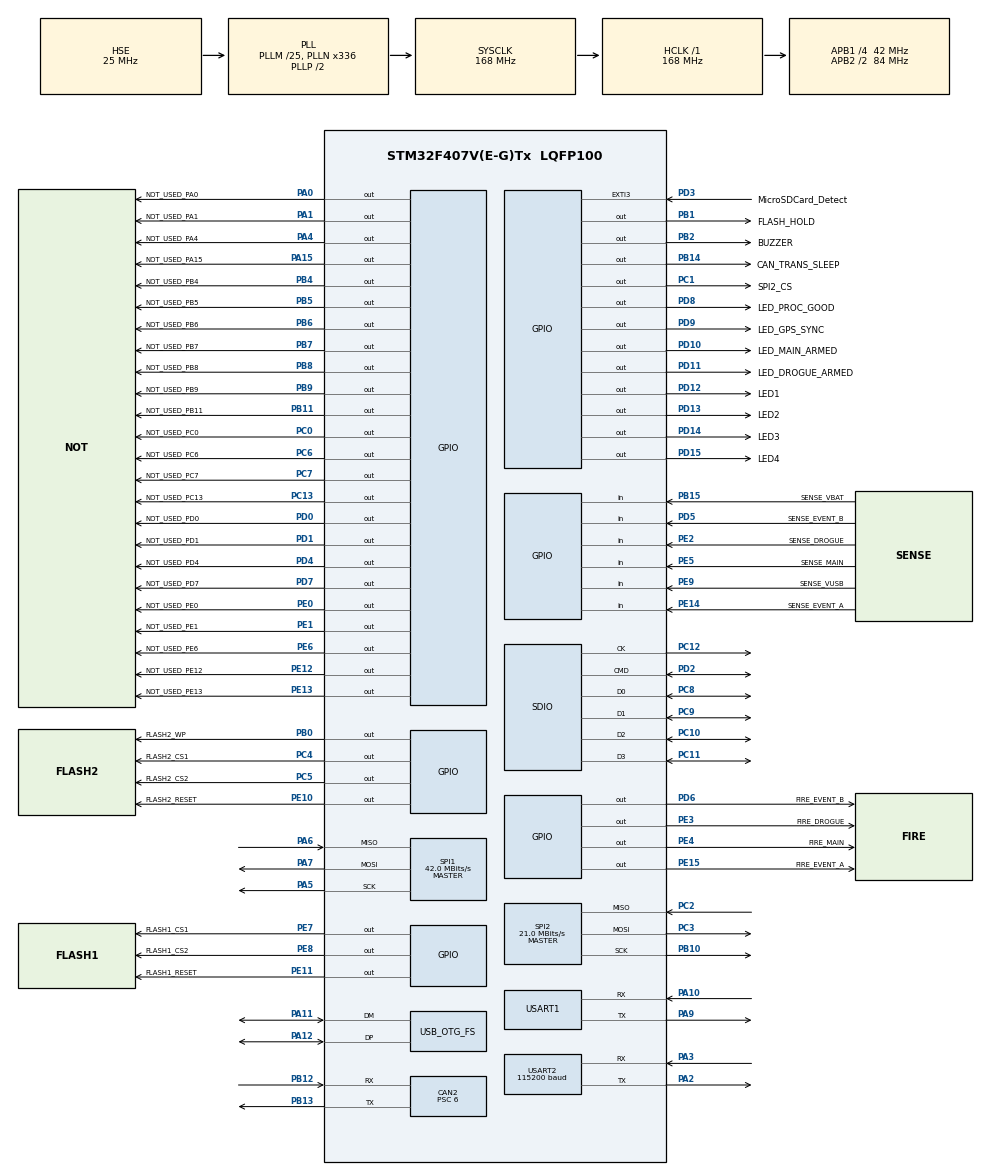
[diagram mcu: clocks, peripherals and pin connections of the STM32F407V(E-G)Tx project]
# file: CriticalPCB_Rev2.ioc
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CAN2.BS1=CAN_BS1_11TQ
CAN2.BS2=CAN_BS2_2TQ
CAN2.CalculateTimeBit=2000
CAN2.CalculateTimeQuantum=142.85714285714286
CAN2.Prescaler=6
Dma.Request0=USART2_TX
Dma.Request1=SDIO
Dma.SDIO.1.Direction=DMA_PERIPH_TO_MEMORY
Dma.SDIO.1.FIFOMode=DMA_FIFOMODE_ENABLE
Dma.SDIO.1.FIFOThreshold=DMA_FIFO_THRESHOLD_FULL
Dma.SDIO.1.Instance=DMA2_Stream3
Dma.SDIO.1.MemBurst=DMA_MBURST_INC4
Dma.SDIO.1.MemDataAlignment=DMA_MDATAALIGN_WORD
Dma.SDIO.1.MemInc=DMA_MINC_ENABLE
Dma.SDIO.1.Mode=DMA_PFCTRL
Dma.SDIO.1.PeriphBurst=DMA_PBURST_INC4
Dma.SDIO.1.PeriphDataAlignment=DMA_PDATAALIGN_WORD
Dma.SDIO.1.PeriphInc=DMA_PINC_DISABLE
Dma.SDIO.1.Priority=DMA_PRIORITY_VERY_HIGH
Dma.USART2_TX.0.Direction=DMA_MEMORY_TO_PERIPH
Dma.USART2_TX.0.FIFOMode=DMA_FIFOMODE_DISABLE
Dma.USART2_TX.0.Instance=DMA1_Stream6
Dma.USART2_TX.0.MemDataAlignment=DMA_MDATAALIGN_BYTE
Dma.USART2_TX.0.MemInc=DMA_MINC_ENABLE
Dma.USART2_TX.0.Mode=DMA_NORMAL
Dma.USART2_TX.0.PeriphDataAlignment=DMA_PDATAALIGN_BYTE
Dma.USART2_TX.0.PeriphInc=DMA_PINC_DISABLE
Dma.USART2_TX.0.Priority=DMA_PRIORITY_VERY_HIGH
FATFS._FS_LOCK=10
Mcu.Family=STM32F4
Mcu.Name=STM32F407V(E-G)Tx
Mcu.Package=LQFP100
NVIC.CAN2_RX0_IRQn=true\:1\:0\:true\:true\:true\:10\:true
NVIC.CAN2_RX1_IRQn=true\:1\:0\:true\:true\:true\:11\:true
NVIC.DMA1_Stream6_IRQn=true\:0\:0\:false\:true\:true\:7\:true
NVIC.DMA2_Stream3_IRQn=true\:0\:0\:false\:true\:true\:9\:true
NVIC.EXTI3_IRQn=true\:1\:0\:true\:true\:true\:4\:true
NVIC.OTG_FS_IRQn=true\:1\:0\:true\:true\:true\:12\:true
NVIC.PriorityGroup=NVIC_PRIORITYGROUP_4
NVIC.SDIO_IRQn=true\:0\:0\:false\:true\:true\:8\:true
NVIC.TIM1_UP_TIM10_IRQn=true\:4\:0\:true\:true\:true\:1\:true
NVIC.TIM2_IRQn=true\:0\:0\:false\:true\:true\:2\:true
NVIC.USART1_IRQn=true\:1\:0\:true\:true\:true\:5\:true
NVIC.USART2_IRQn=true\:1\:0\:true\:true\:true\:6\:true
PA0-WKUP.GPIO_Label=NOT_USED_PA0
PA0-WKUP.GPIO_PuPd=GPIO_PULLDOWN
PA0-WKUP.Signal=GPIO_Output
PA1.GPIO_Label=NOT_USED_PA1
PA1.GPIO_PuPd=GPIO_PULLDOWN
PA1.Signal=GPIO_Output
PA10.GPIO_PuPd=GPIO_PULLUP
PA10.Mode=Asynchronous
PA10.Signal=USART1_RX
PA11.Mode=Device_Only
PA11.Signal=USB_OTG_FS_DM
PA12.Mode=Device_Only
PA12.Signal=USB_OTG_FS_DP
PA13.Mode=Serial_Wire
PA13.Signal=SYS_JTMS-SWDIO
PA14.Mode=Serial_Wire
PA14.Signal=SYS_JTCK-SWCLK
PA15.GPIO_Label=NOT_USED_PA15
PA15.GPIO_PuPd=GPIO_PULLDOWN
PA15.Signal=GPIO_Output
PA2.Mode=Asynchronous
PA2.Signal=USART2_TX
PA3.Mode=Asynchronous
PA3.Signal=USART2_RX
PA4.GPIO_Label=NOT_USED_PA4
PA4.GPIO_PuPd=GPIO_PULLDOWN
PA4.Signal=GPIO_Output
PA5.Mode=Full_Duplex_Master
PA5.Signal=SPI1_SCK
PA6.Mode=Full_Duplex_Master
PA6.Signal=SPI1_MISO
PA7.Mode=Full_Duplex_Master
PA7.Signal=SPI1_MOSI
PA9.GPIO_PuPd=GPIO_PULLUP
PA9.Mode=Asynchronous
PA9.Signal=USART1_TX
PB0.GPIO_Label=FLASH2_WP
PB0.GPIO_PuPd=GPIO_PULLUP
PB0.GPIO_Speed=GPIO_SPEED_FREQ_VERY_HIGH
PB0.PinState=GPIO_PIN_SET
PB0.Signal=GPIO_Output
PB1.GPIO_Label=FLASH_HOLD
PB1.GPIO_PuPd=GPIO_PULLUP
PB1.GPIO_Speed=GPIO_SPEED_FREQ_VERY_HIGH
PB1.PinState=GPIO_PIN_SET
PB1.Signal=GPIO_Output
PB10.Mode=Full_Duplex_Master
PB10.Signal=SPI2_SCK
PB11.GPIO_Label=NOT_USED_PB11
PB11.GPIO_PuPd=GPIO_PULLDOWN
PB11.Signal=GPIO_Output
PB12.GPIO_PuPd=GPIO_PULLUP
PB12.Mode=Slave
PB12.Signal=CAN2_RX
PB13.GPIO_PuPd=GPIO_PULLUP
PB13.Mode=Slave
PB13.Signal=CAN2_TX
PB14.GPIO_Label=CAN_TRANS_SLEEP
PB14.GPIO_PuPd=GPIO_PULLDOWN
PB14.GPIO_Speed=GPIO_SPEED_FREQ_VERY_HIGH
PB14.Signal=GPIO_Output
PB15.GPIO_Label=SENSE_VBAT
PB15.Signal=GPIO_Input
PB2.GPIO_Label=BUZZER
PB2.GPIO_PuPd=GPIO_PULLDOWN
PB2.Signal=GPIO_Output
PB3.Signal=SYS_JTDO-SWO
PB4.GPIO_Label=NOT_USED_PB4
PB4.GPIO_PuPd=GPIO_PULLDOWN
PB4.Signal=GPIO_Output
PB5.GPIO_Label=NOT_USED_PB5
PB5.GPIO_PuPd=GPIO_PULLDOWN
PB5.Signal=GPIO_Output
PB6.GPIO_Label=NOT_USED_PB6
PB6.GPIO_PuPd=GPIO_PULLDOWN
PB6.Signal=GPIO_Output
PB7.GPIO_Label=NOT_USED_PB7
PB7.GPIO_PuPd=GPIO_PULLDOWN
PB7.Signal=GPIO_Output
PB8.GPIO_Label=NOT_USED_PB8
PB8.GPIO_PuPd=GPIO_PULLDOWN
PB8.Signal=GPIO_Output
PB9.GPIO_Label=NOT_USED_PB9
PB9.GPIO_PuPd=GPIO_PULLDOWN
PB9.Signal=GPIO_Output
PC0.GPIO_Label=NOT_USED_PC0
PC0.GPIO_PuPd=GPIO_PULLDOWN
PC0.Signal=GPIO_Output
PC1.GPIO_Label=SPI2_CS
PC1.GPIO_PuPd=GPIO_PULLUP
PC1.GPIO_Speed=GPIO_SPEED_FREQ_VERY_HIGH
PC1.PinState=GPIO_PIN_SET
PC1.Signal=GPIO_Output
PC10.GPIO_PuPd=GPIO_PULLUP
PC10.Mode=SD_4_bits_Wide_bus
PC10.Signal=SDIO_D2
PC11.GPIO_PuPd=GPIO_PULLUP
PC11.Mode=SD_4_bits_Wide_bus
PC11.Signal=SDIO_D3
PC12.GPIO_PuPd=GPIO_PULLUP
PC12.Mode=SD_4_bits_Wide_bus
PC12.Signal=SDIO_CK
PC13-ANTI_TAMP.GPIO_Label=NOT_USED_PC13
PC13-ANTI_TAMP.GPIO_PuPd=GPIO_PULLDOWN
PC13-ANTI_TAMP.Signal=GPIO_Output
PC14-OSC32_IN.Mode=LSE-External-Oscillator
PC14-OSC32_IN.Signal=RCC_OSC32_IN
PC15-OSC32_OUT.Mode=LSE-External-Oscillator
PC15-OSC32_OUT.Signal=RCC_OSC32_OUT
PC2.Mode=Full_Duplex_Master
PC2.Signal=SPI2_MISO
PC3.Mode=Full_Duplex_Master
PC3.Signal=SPI2_MOSI
PC4.GPIO_Label=FLASH2_CS1
PC4.GPIO_PuPd=GPIO_PULLUP
PC4.GPIO_Speed=GPIO_SPEED_FREQ_VERY_HIGH
PC4.PinState=GPIO_PIN_SET
PC4.Signal=GPIO_Output
PC5.GPIO_Label=FLASH2_CS2
PC5.GPIO_PuPd=GPIO_PULLUP
PC5.GPIO_Speed=GPIO_SPEED_FREQ_VERY_HIGH
PC5.PinState=GPIO_PIN_SET
PC5.Signal=GPIO_Output
PC6.GPIO_Label=NOT_USED_PC6
PC6.GPIO_PuPd=GPIO_PULLDOWN
PC6.Signal=GPIO_Output
PC7.GPIO_Label=NOT_USED_PC7
PC7.GPIO_PuPd=GPIO_PULLDOWN
PC7.Signal=GPIO_Output
PC8.GPIO_PuPd=GPIO_PULLUP
PC8.Mode=SD_4_bits_Wide_bus
PC8.Signal=SDIO_D0
PC9.GPIO_PuPd=GPIO_PULLUP
PC9.Mode=SD_4_bits_Wide_bus
PC9.Signal=SDIO_D1
PD0.GPIO_Label=NOT_USED_PD0
PD0.GPIO_PuPd=GPIO_PULLDOWN
PD0.Signal=GPIO_Output
PD1.GPIO_Label=NOT_USED_PD1
PD1.GPIO_PuPd=GPIO_PULLDOWN
PD1.Signal=GPIO_Output
PD10.GPIO_Label=LED_MAIN_ARMED
PD10.GPIO_PuPd=GPIO_PULLDOWN
PD10.Signal=GPIO_Output
PD11.GPIO_Label=LED_DROGUE_ARMED
PD11.GPIO_PuPd=GPIO_PULLDOWN
PD11.Signal=GPIO_Output
PD12.GPIO_Label=LED1
PD12.GPIO_PuPd=GPIO_PULLDOWN
PD12.Signal=GPIO_Output
PD13.GPIO_Label=LED2
PD13.GPIO_PuPd=GPIO_PULLDOWN
PD13.Signal=GPIO_Output
PD14.GPIO_Label=LED3
PD14.GPIO_PuPd=GPIO_PULLDOWN
PD14.Signal=GPIO_Output
PD15.GPIO_Label=LED4
PD15.GPIO_PuPd=GPIO_PULLDOWN
PD15.Signal=GPIO_Output
PD2.GPIO_PuPd=GPIO_PULLUP
PD2.Mode=SD_4_bits_Wide_bus
PD2.Signal=SDIO_CMD
PD3.GPIO_Label=MicroSDCard_Detect
PD3.GPIO_ModeDefaultEXTI=GPIO_MODE_IT_RISING_FALLING
PD3.GPIO_PuPd=GPIO_PULLDOWN
PD3.Signal=GPXTI3
PD4.GPIO_Label=NOT_USED_PD4
PD4.GPIO_PuPd=GPIO_PULLDOWN
PD4.Signal=GPIO_Output
PD5.GPIO_Label=SENSE_EVENT_B
PD5.GPIO_PuPd=GPIO_PULLUP
PD5.Signal=GPIO_Input
PD6.GPIO_Label=FIRE_EVENT_B
PD6.GPIO_PuPd=GPIO_PULLDOWN
PD6.GPIO_Speed=GPIO_SPEED_FREQ_VERY_HIGH
PD6.Signal=GPIO_Output
PD7.GPIO_Label=NOT_USED_PD7
PD7.GPIO_PuPd=GPIO_PULLDOWN
PD7.Signal=GPIO_Output
PD8.GPIO_Label=LED_PROC_GOOD
PD8.GPIO_PuPd=GPIO_PULLDOWN
PD8.Signal=GPIO_Output
PD9.GPIO_Label=LED_GPS_SYNC
PD9.GPIO_PuPd=GPIO_PULLDOWN
PD9.Signal=GPIO_Output
PE0.GPIO_Label=NOT_USED_PE0
PE0.GPIO_PuPd=GPIO_PULLDOWN
PE0.Signal=GPIO_Output
PE1.GPIO_Label=NOT_USED_PE1
PE1.GPIO_PuPd=GPIO_PULLDOWN
PE1.Signal=GPIO_Output
PE10.GPIO_Label=FLASH2_RESET
PE10.GPIO_PuPd=GPIO_PULLUP
PE10.GPIO_Speed=GPIO_SPEED_FREQ_VERY_HIGH
PE10.PinState=GPIO_PIN_SET
PE10.Signal=GPIO_Output
PE11.GPIO_Label=FLASH1_RESET
PE11.GPIO_PuPd=GPIO_PULLUP
PE11.GPIO_Speed=GPIO_SPEED_FREQ_VERY_HIGH
PE11.PinState=GPIO_PIN_SET
PE11.Signal=GPIO_Output
PE12.GPIO_Label=NOT_USED_PE12
PE12.GPIO_PuPd=GPIO_PULLDOWN
PE12.Signal=GPIO_Output
PE13.GPIO_Label=NOT_USED_PE13
PE13.GPIO_PuPd=GPIO_PULLDOWN
PE13.Signal=GPIO_Output
PE14.GPIO_Label=SENSE_EVENT_A
PE14.GPIO_PuPd=GPIO_PULLUP
PE14.Signal=GPIO_Input
PE15.GPIO_Label=FIRE_EVENT_A
PE15.GPIO_PuPd=GPIO_PULLDOWN
PE15.GPIO_Speed=GPIO_SPEED_FREQ_VERY_HIGH
PE15.Signal=GPIO_Output
PE2.GPIO_Label=SENSE_DROGUE
PE2.GPIO_PuPd=GPIO_PULLUP
PE2.Signal=GPIO_Input
PE3.GPIO_Label=FIRE_DROGUE
PE3.GPIO_PuPd=GPIO_PULLDOWN
PE3.GPIO_Speed=GPIO_SPEED_FREQ_VERY_HIGH
PE3.Signal=GPIO_Output
PE4.GPIO_Label=FIRE_MAIN
PE4.GPIO_PuPd=GPIO_PULLDOWN
PE4.GPIO_Speed=GPIO_SPEED_FREQ_VERY_HIGH
PE4.Signal=GPIO_Output
PE5.GPIO_Label=SENSE_MAIN
PE5.GPIO_PuPd=GPIO_PULLUP
PE5.Signal=GPIO_Input
PE6.GPIO_Label=NOT_USED_PE6
PE6.GPIO_PuPd=GPIO_PULLDOWN
PE6.Signal=GPIO_Output
PE7.GPIO_Label=FLASH1_CS1
PE7.GPIO_PuPd=GPIO_PULLUP
PE7.GPIO_Speed=GPIO_SPEED_FREQ_VERY_HIGH
PE7.PinState=GPIO_PIN_SET
PE7.Signal=GPIO_Output
PE8.GPIO_Label=FLASH1_CS2
PE8.GPIO_PuPd=GPIO_PULLUP
PE8.GPIO_Speed=GPIO_SPEED_FREQ_VERY_HIGH
PE8.PinState=GPIO_PIN_SET
PE8.Signal=GPIO_Output
PE9.GPIO_Label=SENSE_VUSB
PE9.GPIO_PuPd=GPIO_PULLUP
PE9.Signal=GPIO_Input
PH0-OSC_IN.Mode=HSE-External-Clock-Source
PH0-OSC_IN.Signal=RCC_OSC_IN
PH1-OSC_OUT.Mode=HSE-External-Clock-Source
PH1-OSC_OUT.Signal=RCC_OSC_OUT
ProjectManager.HeapSize=0x200
ProjectManager.StackSize=0x400
ProjectManager.TargetToolchain=Makefile
RCC.48MHZClocksFreq_Value=48000000
RCC.AHBCLKDivider=RCC_SYSCLK_DIV1
RCC.AHBFreq_Value=168000000
RCC.APB1CLKDivider=RCC_HCLK_DIV4
RCC.APB1Freq_Value=42000000
RCC.APB1TimFreq_Value=84000000
RCC.APB2CLKDivider=RCC_HCLK_DIV2
RCC.APB2Freq_Value=84000000
RCC.APB2TimFreq_Value=168000000
RCC.CortexFreq_Value=168000000
RCC.Cortex_Div=SYSTICK_CLKSOURCE_HCLK
RCC.HCLKFreq_Value=168000000
RCC.HSE_VALUE=25000000
RCC.HSI_VALUE=16000000
RCC.OscillatorTypeHSI=RCC_OSCILLATORTYPE_HSI
RCC.PLLM=25
RCC.PLLN=336
RCC.PLLP=RCC_PLLP_DIV2
RCC.PLLQ=7
RCC.RCC_MCODiv1=RCC_MCODIV_1
RCC.RCC_MCODiv2=RCC_MCODIV_1
RCC.RCC_RTC_Clock_Source=RCC_RTCCLKSOURCE_LSE
RCC.RCC_RTC_Clock_SourceVirtual=RCC_RTCCLKSOURCE_LSE
RCC.RCC_RTC_Clock_Source_FROM_HSE=RCC_RTCCLKSOURCE_HSE_DIV2
RCC.SYSCLKFreq_VALUE=168000000
RCC.SYSCLKSource=RCC_SYSCLKSOURCE_PLLCLK
RCC.VCOOutputFreq_Value=336000000
RTC.Alarm=RTC_ALARM_A
SPI1.CalculateBaudRate=42.0 MBits/s
SPI1.Direction=SPI_DIRECTION_2LINES
SPI1.Mode=SPI_MODE_MASTER
SPI1.VirtualType=VM_MASTER
SPI2.CalculateBaudRate=21.0 MBits/s
SPI2.Direction=SPI_DIRECTION_2LINES
SPI2.Mode=SPI_MODE_MASTER
SPI2.VirtualType=VM_MASTER
TIM1.Period=0x7FFF
TIM1.Prescaler=256
TIM1.TIM_MasterOutputTrigger=TIM_TRGO_UPDATE
TIM1.TIM_MasterSlaveMode=TIM_MASTERSLAVEMODE_ENABLE
TIM2.Period=100
TIM3.Period=20
USART1.VirtualMode=VM_ASYNC
USART2.BaudRate=115200
USART2.VirtualMode=VM_ASYNC
USB_DEVICE.CLASS_NAME_FS=CDC
USB_DEVICE.MANUFACTURER_STRING-CDC_FS=RockETS Master Race
USB_DEVICE.VirtualModeFS=Cdc_FS
USB_OTG_FS.VirtualMode=Device_Only
USB_OTG_FS.dev_endpoints=4
VP_CRC_VS_CRC.Mode=CRC_Activate
VP_FATFS_VS_SDIO.Mode=SDIO
VP_RTC_VS_RTC_Activate.Mode=RTC_Enabled
VP_RTC_VS_RTC_Alarm_A_Intern.Mode=Alarm A
VP_RTC_VS_RTC_Calendar.Mode=RTC_Calendar
VP_TIM1_VS_ClockSourceINT.Mode=Internal
VP_TIM1_VS_ClockSourceITR.Mode=TriggerSource_ITR0
VP_TIM2_VS_ClockSourceITR.Mode=TriggerSource_ITR0
VP_TIM2_VS_ControllerModeClock.Mode=Clock Mode
VP_TIM3_VS_ClockSourceITR.Mode=TriggerSource_ITR0
VP_TIM3_VS_ControllerModeClock.Mode=Clock Mode
VP_USB_DEVICE_VS_USB_DEVICE_CDC_FS.Mode=CDC_FS
board=CriticalPCB_Rev2

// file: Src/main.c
/**
  ******************************************************************************
  * File Name          : main.c
  * Description        : Main program body
  ******************************************************************************
  * This notice applies to any and all portions of this file
  * that are not between comment pairs USER CODE BEGIN and
  * USER CODE END. Other portions of this file, whether
  * inserted by the user or by software development tools
  * are owned by their respective copyright owners.
  *
  * Copyright (c) 2019 STMicroelectronics International N.V.
  * All rights reserved.
  *
  * Redistribution and use in source and binary forms, with or without
  * modification, are permitted, provided that the following conditions are met:
  *
  * 1. Redistribution of source code must retain the above copyright notice,
  *    this list of conditions and the following disclaimer.
  * 2. Redistributions in binary form must reproduce the above copyright notice,
  *    this list of conditions and the following disclaimer in the documentation
  *    and/or other materials provided with the distribution.
  * 3. Neither the name of STMicroelectronics nor the names of other
  *    contributors to this software may be used to endorse or promote products
  *    derived from this software without specific written permission.
  * 4. This software, including modifications and/or derivative works of this
  *    software, must execute solely and exclusively on microcontroller or
  *    microprocessor devices manufactured by or for STMicroelectronics.
  * 5. Redistribution and use of this software other than as permitted under
  *    this license is void and will automatically terminate your rights under
  *    this license.
  *
  * THIS SOFTWARE IS PROVIDED BY STMICROELECTRONICS AND CONTRIBUTORS "AS IS"
  * AND ANY EXPRESS, IMPLIED OR STATUTORY WARRANTIES, INCLUDING, BUT NOT
  * LIMITED TO, THE IMPLIED WARRANTIES OF MERCHANTABILITY, FITNESS FOR A
  * PARTICULAR PURPOSE AND NON-INFRINGEMENT OF THIRD PARTY INTELLECTUAL PROPERTY
  * RIGHTS ARE DISCLAIMED TO THE FULLEST EXTENT PERMITTED BY LAW. IN NO EVENT
  * SHALL STMICROELECTRONICS OR CONTRIBUTORS BE LIABLE FOR ANY DIRECT, INDIRECT,
  * INCIDENTAL, SPECIAL, EXEMPLARY, OR CONSEQUENTIAL DAMAGES (INCLUDING, BUT NOT
  * LIMITED TO, PROCUREMENT OF SUBSTITUTE GOODS OR SERVICES; LOSS OF USE, DATA,
  * OR PROFITS; OR BUSINESS INTERRUPTION) HOWEVER CAUSED AND ON ANY THEORY OF
  * LIABILITY, WHETHER IN CONTRACT, STRICT LIABILITY, OR TORT (INCLUDING
  * NEGLIGENCE OR OTHERWISE) ARISING IN ANY WAY OUT OF THE USE OF THIS SOFTWARE,
  * EVEN IF ADVISED OF THE POSSIBILITY OF SUCH DAMAGE.
  *
  ******************************************************************************
  */
#include "main.h"
#include "stm32f4xx_hal.h"
#include "can.h"
#include "crc.h"
#include "dma.h"
#include "fatfs.h"
#include "rtc.h"
#include "sdio.h"
#include "spi.h"
#include "tim.h"
#include "usart.h"
#include "usb_device.h"
#include "gpio.h"

/* USER CODE BEGIN PV */
/* Private variables ---------------------------------------------------------*/

/* USER CODE END PV */

void SystemClock_Config(void);
static void MX_NVIC_Init(void);

/* USER CODE BEGIN PFP */
/* Private function prototypes -----------------------------------------------*/

/* USER CODE END PFP */

int main(void)
{

  /* MCU Configuration----------------------------------------------------------*/

  /* Reset of all peripherals, Initializes the Flash interface and the Systick. */
  HAL_Init();

  /* Configure the system clock */
  SystemClock_Config();

  /* Initialize all configured peripherals */
  MX_GPIO_Init();
  MX_DMA_Init();
  MX_CAN2_Init();
  MX_RTC_Init();
  MX_SDIO_SD_Init();
  MX_SPI1_Init();
  MX_SPI2_Init();
  MX_TIM1_Init();
  MX_TIM2_Init();
  MX_TIM3_Init();
  MX_USART1_UART_Init();
  MX_USART2_UART_Init();
  MX_FATFS_Init();
  MX_USB_DEVICE_Init();
  MX_CRC_Init();

  /* Initialize interrupts */
  MX_NVIC_Init();

  /* USER CODE BEGIN 2 */

  //start timer 1 with its global interrupt
  //callback is used in Main_Gemma.c to run main routine
  HAL_TIM_Base_Start_IT(&htim1);

  //start timer 2 with its global interrupt
  //callback is used in Main_Gemma.c to save on SD
  HAL_TIM_Base_Start_IT(&htim2);

  //start timer 3 with its global interrupt
  //callback is used in Main_Gemma.c to send data...
  //big data must be sent throught dma
  HAL_TIM_Base_Start_IT(&htim3);

  //start CAN2 reception for expension board
  //callback is in inertial_station.c
  HAL_CAN_Receive_IT(&hcan2, CAN_FIFO0);

  /* USER CODE END 2 */

  /* Infinite loop */
  while (1) {

  }

}

/** System Clock Configuration
*/
void SystemClock_Config(void)
{

  RCC_OscInitTypeDef RCC_OscInitStruct;
  RCC_ClkInitTypeDef RCC_ClkInitStruct;
  RCC_PeriphCLKInitTypeDef PeriphClkInitStruct;

    /**Configure the main internal regulator output voltage
    */
  __HAL_RCC_PWR_CLK_ENABLE();

  __HAL_PWR_VOLTAGESCALING_CONFIG(PWR_REGULATOR_VOLTAGE_SCALE1);

    /**Initializes the CPU, AHB and APB busses clocks
    */
  RCC_OscInitStruct.OscillatorType = RCC_OSCILLATORTYPE_HSI|RCC_OSCILLATORTYPE_HSE
                              |RCC_OSCILLATORTYPE_LSE;
  RCC_OscInitStruct.HSEState = RCC_HSE_BYPASS;
  RCC_OscInitStruct.LSEState = RCC_LSE_ON;
  RCC_OscInitStruct.PLL.PLLState = RCC_PLL_ON;
  RCC_OscInitStruct.PLL.PLLSource = RCC_PLLSOURCE_HSE;
  RCC_OscInitStruct.PLL.PLLM = 25;
  RCC_OscInitStruct.PLL.PLLN = 336;
  RCC_OscInitStruct.PLL.PLLP = RCC_PLLP_DIV2;
  RCC_OscInitStruct.PLL.PLLQ = 7;
  if (HAL_RCC_OscConfig(&RCC_OscInitStruct) != HAL_OK)
  {
    _Error_Handler(__FILE__, __LINE__);
  }

    /**Initializes the CPU, AHB and APB busses clocks
    */
  RCC_ClkInitStruct.ClockType = RCC_CLOCKTYPE_HCLK|RCC_CLOCKTYPE_SYSCLK
                              |RCC_CLOCKTYPE_PCLK1|RCC_CLOCKTYPE_PCLK2;
  RCC_ClkInitStruct.SYSCLKSource = RCC_SYSCLKSOURCE_PLLCLK;
  RCC_ClkInitStruct.AHBCLKDivider = RCC_SYSCLK_DIV1;
  RCC_ClkInitStruct.APB1CLKDivider = RCC_HCLK_DIV4;
  RCC_ClkInitStruct.APB2CLKDivider = RCC_HCLK_DIV2;

  if (HAL_RCC_ClockConfig(&RCC_ClkInitStruct, FLASH_LATENCY_5) != HAL_OK)
  {
    _Error_Handler(__FILE__, __LINE__);
  }

  PeriphClkInitStruct.PeriphClockSelection = RCC_PERIPHCLK_RTC;
  PeriphClkInitStruct.RTCClockSelection = RCC_RTCCLKSOURCE_LSE;
  if (HAL_RCCEx_PeriphCLKConfig(&PeriphClkInitStruct) != HAL_OK)
  {
    _Error_Handler(__FILE__, __LINE__);
  }

    /**Configure the Systick interrupt time
    */
  HAL_SYSTICK_Config(HAL_RCC_GetHCLKFreq()/1000);

    /**Configure the Systick
    */
  HAL_SYSTICK_CLKSourceConfig(SYSTICK_CLKSOURCE_HCLK);

  /* SysTick_IRQn interrupt configuration */
  HAL_NVIC_SetPriority(SysTick_IRQn, 0, 0);
}

/** NVIC Configuration
*/
static void MX_NVIC_Init(void)
{
  /* TIM1_UP_TIM10_IRQn interrupt configuration */
  HAL_NVIC_SetPriority(TIM1_UP_TIM10_IRQn, 4, 0);
  HAL_NVIC_EnableIRQ(TIM1_UP_TIM10_IRQn);
  /* TIM2_IRQn interrupt configuration */
  HAL_NVIC_SetPriority(TIM2_IRQn, 0, 0);
  HAL_NVIC_EnableIRQ(TIM2_IRQn);
  /* EXTI3_IRQn interrupt configuration */
  HAL_NVIC_SetPriority(EXTI3_IRQn, 1, 0);
  HAL_NVIC_EnableIRQ(EXTI3_IRQn);
  /* USART1_IRQn interrupt configuration */
  HAL_NVIC_SetPriority(USART1_IRQn, 1, 0);
  HAL_NVIC_EnableIRQ(USART1_IRQn);
  /* USART2_IRQn interrupt configuration */
  HAL_NVIC_SetPriority(USART2_IRQn, 1, 0);
  HAL_NVIC_EnableIRQ(USART2_IRQn);
  /* DMA1_Stream6_IRQn interrupt configuration */
  HAL_NVIC_SetPriority(DMA1_Stream6_IRQn, 0, 0);
  HAL_NVIC_EnableIRQ(DMA1_Stream6_IRQn);
  /* SDIO_IRQn interrupt configuration */
  HAL_NVIC_SetPriority(SDIO_IRQn, 0, 0);
  HAL_NVIC_EnableIRQ(SDIO_IRQn);
  /* DMA2_Stream3_IRQn interrupt configuration */
  HAL_NVIC_SetPriority(DMA2_Stream3_IRQn, 0, 0);
  HAL_NVIC_EnableIRQ(DMA2_Stream3_IRQn);
  /* CAN2_RX0_IRQn interrupt configuration */
  HAL_NVIC_SetPriority(CAN2_RX0_IRQn, 1, 0);
  HAL_NVIC_EnableIRQ(CAN2_RX0_IRQn);
  /* CAN2_RX1_IRQn interrupt configuration */
  HAL_NVIC_SetPriority(CAN2_RX1_IRQn, 1, 0);
  HAL_NVIC_EnableIRQ(CAN2_RX1_IRQn);
  /* OTG_FS_IRQn interrupt configuration */
  HAL_NVIC_SetPriority(OTG_FS_IRQn, 1, 0);
  HAL_NVIC_EnableIRQ(OTG_FS_IRQn);
}

void _Error_Handler(char * file, int line)
{
  while(1)
  {
  }
}

/************************ (C) COPYRIGHT STMicroelectronics *****END OF FILE****/
